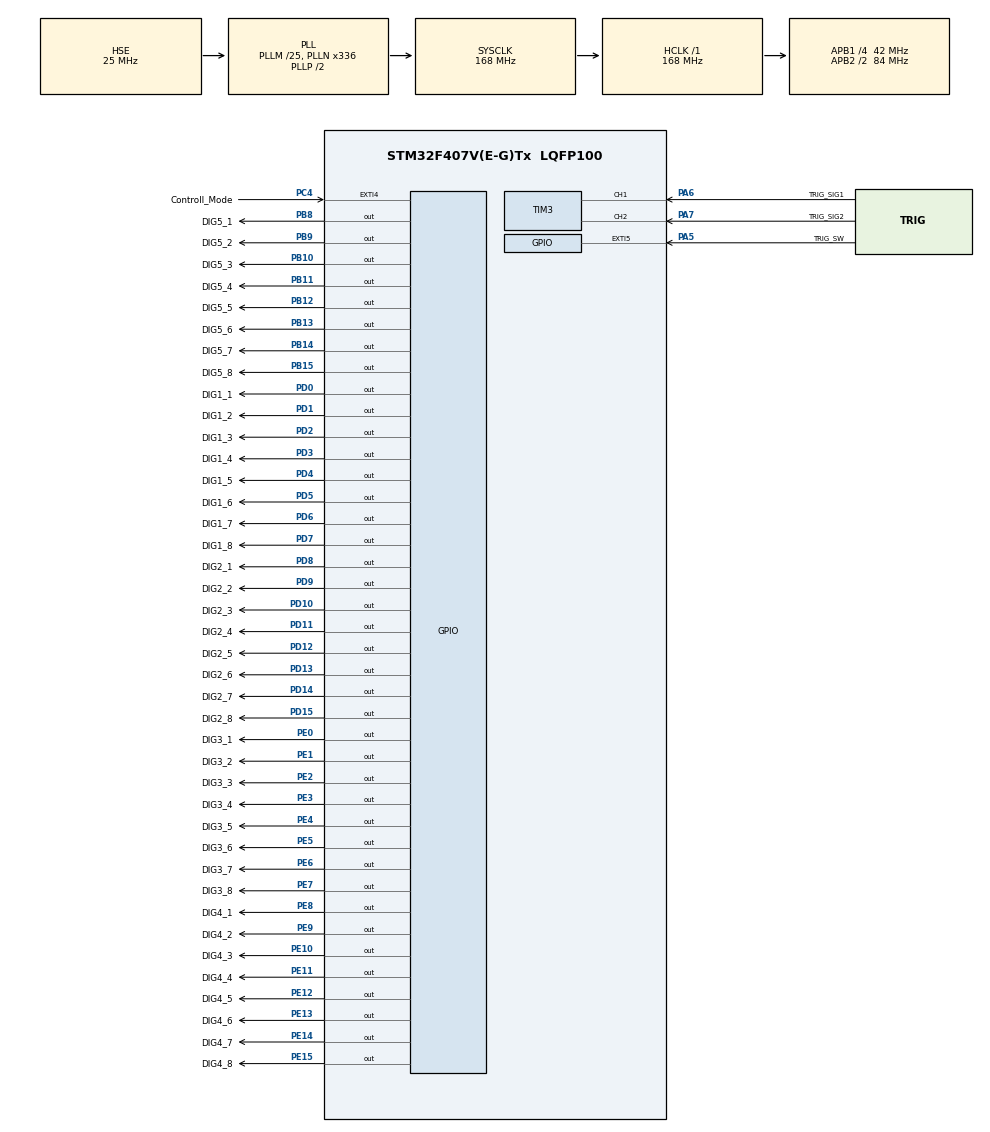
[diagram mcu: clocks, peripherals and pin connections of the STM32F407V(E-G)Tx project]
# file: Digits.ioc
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Mcu.Family=STM32F4
Mcu.Name=STM32F407V(E-G)Tx
Mcu.Package=LQFP100
NVIC.EXTI4_IRQn=true\:2\:0\:false\:false\:true\:true\:true\:true
NVIC.EXTI9_5_IRQn=true\:1\:0\:false\:false\:true\:true\:true\:true
NVIC.PriorityGroup=NVIC_PRIORITYGROUP_4
NVIC.TIM2_IRQn=true\:0\:0\:false\:false\:true\:true\:true\:true
NVIC.TIM3_IRQn=true\:0\:0\:false\:false\:true\:true\:true\:true
PA13.Mode=Serial_Wire
PA13.Signal=SYS_JTMS-SWDIO
PA14.Mode=Serial_Wire
PA14.Signal=SYS_JTCK-SWCLK
PA5.GPIO_Label=TRIG_SW
PA5.GPIO_ModeDefaultEXTI=GPIO_MODE_IT_RISING_FALLING
PA5.Signal=GPXTI5
PA6.GPIO_Label=TRIG_SIG1
PA6.Signal=S_TIM3_CH1
PA7.GPIO_Label=TRIG_SIG2
PA7.Signal=S_TIM3_CH2
PB10.GPIO_Label=DIG5_3
PB10.GPIO_Speed=GPIO_SPEED_FREQ_HIGH
PB10.PinState=GPIO_PIN_SET
PB10.Signal=GPIO_Output
PB11.GPIO_Label=DIG5_4
PB11.GPIO_Speed=GPIO_SPEED_FREQ_HIGH
PB11.PinState=GPIO_PIN_SET
PB11.Signal=GPIO_Output
PB12.GPIO_Label=DIG5_5
PB12.GPIO_Speed=GPIO_SPEED_FREQ_HIGH
PB12.PinState=GPIO_PIN_SET
PB12.Signal=GPIO_Output
PB13.GPIO_Label=DIG5_6
PB13.GPIO_Speed=GPIO_SPEED_FREQ_HIGH
PB13.PinState=GPIO_PIN_SET
PB13.Signal=GPIO_Output
PB14.GPIO_Label=DIG5_7
PB14.GPIO_Speed=GPIO_SPEED_FREQ_HIGH
PB14.PinState=GPIO_PIN_SET
PB14.Signal=GPIO_Output
PB15.GPIO_Label=DIG5_8
PB15.GPIO_Speed=GPIO_SPEED_FREQ_HIGH
PB15.PinState=GPIO_PIN_SET
PB15.Signal=GPIO_Output
PB8.GPIO_Label=DIG5_1
PB8.GPIO_Speed=GPIO_SPEED_FREQ_HIGH
PB8.PinState=GPIO_PIN_SET
PB8.Signal=GPIO_Output
PB9.GPIO_Label=DIG5_2
PB9.GPIO_Speed=GPIO_SPEED_FREQ_HIGH
PB9.PinState=GPIO_PIN_SET
PB9.Signal=GPIO_Output
PC4.GPIO_Label=Controll_Mode
PC4.GPIO_ModeDefaultEXTI=GPIO_MODE_IT_RISING_FALLING
PC4.Signal=GPXTI4
PD0.GPIO_Label=DIG1_1
PD0.GPIO_Speed=GPIO_SPEED_FREQ_HIGH
PD0.PinState=GPIO_PIN_SET
PD0.Signal=GPIO_Output
PD1.GPIO_Label=DIG1_2
PD1.GPIO_Speed=GPIO_SPEED_FREQ_HIGH
PD1.PinState=GPIO_PIN_SET
PD1.Signal=GPIO_Output
PD10.GPIO_Label=DIG2_3
PD10.GPIO_Speed=GPIO_SPEED_FREQ_HIGH
PD10.PinState=GPIO_PIN_SET
PD10.Signal=GPIO_Output
PD11.GPIO_Label=DIG2_4
PD11.GPIO_Speed=GPIO_SPEED_FREQ_HIGH
PD11.PinState=GPIO_PIN_SET
PD11.Signal=GPIO_Output
PD12.GPIO_Label=DIG2_5
PD12.GPIO_Speed=GPIO_SPEED_FREQ_HIGH
PD12.PinState=GPIO_PIN_SET
PD12.Signal=GPIO_Output
PD13.GPIO_Label=DIG2_6
PD13.GPIO_Speed=GPIO_SPEED_FREQ_HIGH
PD13.PinState=GPIO_PIN_SET
PD13.Signal=GPIO_Output
PD14.GPIO_Label=DIG2_7
PD14.GPIO_Speed=GPIO_SPEED_FREQ_HIGH
PD14.PinState=GPIO_PIN_SET
PD14.Signal=GPIO_Output
PD15.GPIO_Label=DIG2_8
PD15.GPIO_Speed=GPIO_SPEED_FREQ_HIGH
PD15.PinState=GPIO_PIN_SET
PD15.Signal=GPIO_Output
PD2.GPIO_Label=DIG1_3
PD2.GPIO_Speed=GPIO_SPEED_FREQ_HIGH
PD2.PinState=GPIO_PIN_SET
PD2.Signal=GPIO_Output
PD3.GPIO_Label=DIG1_4
PD3.GPIO_Speed=GPIO_SPEED_FREQ_HIGH
PD3.PinState=GPIO_PIN_SET
PD3.Signal=GPIO_Output
PD4.GPIO_Label=DIG1_5
PD4.GPIO_Speed=GPIO_SPEED_FREQ_HIGH
PD4.PinState=GPIO_PIN_SET
PD4.Signal=GPIO_Output
PD5.GPIO_Label=DIG1_6
PD5.GPIO_Speed=GPIO_SPEED_FREQ_HIGH
PD5.PinState=GPIO_PIN_SET
PD5.Signal=GPIO_Output
PD6.GPIO_Label=DIG1_7
PD6.GPIO_Speed=GPIO_SPEED_FREQ_HIGH
PD6.PinState=GPIO_PIN_SET
PD6.Signal=GPIO_Output
PD7.GPIO_Label=DIG1_8
PD7.GPIO_Speed=GPIO_SPEED_FREQ_HIGH
PD7.PinState=GPIO_PIN_SET
PD7.Signal=GPIO_Output
PD8.GPIO_Label=DIG2_1
PD8.GPIO_Speed=GPIO_SPEED_FREQ_HIGH
PD8.PinState=GPIO_PIN_SET
PD8.Signal=GPIO_Output
PD9.GPIO_Label=DIG2_2
PD9.GPIO_Speed=GPIO_SPEED_FREQ_HIGH
PD9.PinState=GPIO_PIN_SET
PD9.Signal=GPIO_Output
PE0.GPIO_Label=DIG3_1
PE0.GPIO_Speed=GPIO_SPEED_FREQ_HIGH
PE0.PinState=GPIO_PIN_SET
PE0.Signal=GPIO_Output
PE1.GPIO_Label=DIG3_2
PE1.GPIO_Speed=GPIO_SPEED_FREQ_HIGH
PE1.PinState=GPIO_PIN_SET
PE1.Signal=GPIO_Output
PE10.GPIO_Label=DIG4_3
PE10.GPIO_Speed=GPIO_SPEED_FREQ_HIGH
PE10.PinState=GPIO_PIN_SET
PE10.Signal=GPIO_Output
PE11.GPIO_Label=DIG4_4
PE11.GPIO_Speed=GPIO_SPEED_FREQ_HIGH
PE11.PinState=GPIO_PIN_SET
PE11.Signal=GPIO_Output
PE12.GPIO_Label=DIG4_5
PE12.GPIO_Speed=GPIO_SPEED_FREQ_HIGH
PE12.PinState=GPIO_PIN_SET
PE12.Signal=GPIO_Output
PE13.GPIO_Label=DIG4_6
PE13.GPIO_Speed=GPIO_SPEED_FREQ_HIGH
PE13.PinState=GPIO_PIN_SET
PE13.Signal=GPIO_Output
PE14.GPIO_Label=DIG4_7
PE14.GPIO_Speed=GPIO_SPEED_FREQ_HIGH
PE14.PinState=GPIO_PIN_SET
PE14.Signal=GPIO_Output
PE15.GPIO_Label=DIG4_8
PE15.GPIO_Speed=GPIO_SPEED_FREQ_HIGH
PE15.PinState=GPIO_PIN_SET
PE15.Signal=GPIO_Output
PE2.GPIO_Label=DIG3_3
PE2.GPIO_Speed=GPIO_SPEED_FREQ_HIGH
PE2.PinState=GPIO_PIN_SET
PE2.Signal=GPIO_Output
PE3.GPIO_Label=DIG3_4
PE3.GPIO_Speed=GPIO_SPEED_FREQ_HIGH
PE3.PinState=GPIO_PIN_SET
PE3.Signal=GPIO_Output
PE4.GPIO_Label=DIG3_5
PE4.GPIO_Speed=GPIO_SPEED_FREQ_HIGH
PE4.PinState=GPIO_PIN_SET
PE4.Signal=GPIO_Output
PE5.GPIO_Label=DIG3_6
PE5.GPIO_Speed=GPIO_SPEED_FREQ_HIGH
PE5.PinState=GPIO_PIN_SET
PE5.Signal=GPIO_Output
PE6.GPIO_Label=DIG3_7
PE6.GPIO_Speed=GPIO_SPEED_FREQ_HIGH
PE6.PinState=GPIO_PIN_SET
PE6.Signal=GPIO_Output
PE7.GPIO_Label=DIG3_8
PE7.GPIO_Speed=GPIO_SPEED_FREQ_HIGH
PE7.PinState=GPIO_PIN_SET
PE7.Signal=GPIO_Output
PE8.GPIO_Label=DIG4_1
PE8.GPIO_Speed=GPIO_SPEED_FREQ_HIGH
PE8.PinState=GPIO_PIN_SET
PE8.Signal=GPIO_Output
PE9.GPIO_Label=DIG4_2
PE9.GPIO_Speed=GPIO_SPEED_FREQ_HIGH
PE9.PinState=GPIO_PIN_SET
PE9.Signal=GPIO_Output
PH0-OSC_IN.Mode=HSE-External-Oscillator
PH0-OSC_IN.Signal=RCC_OSC_IN
PH1-OSC_OUT.Mode=HSE-External-Oscillator
PH1-OSC_OUT.Signal=RCC_OSC_OUT
ProjectManager.HeapSize=0x200
ProjectManager.StackSize=0x400
ProjectManager.TargetToolchain=MDK-ARM V5
RCC.48MHZClocksFreq_Value=48000000
RCC.AHBFreq_Value=168000000
RCC.APB1CLKDivider=RCC_HCLK_DIV4
RCC.APB1Freq_Value=42000000
RCC.APB1TimFreq_Value=84000000
RCC.APB2CLKDivider=RCC_HCLK_DIV2
RCC.APB2Freq_Value=84000000
RCC.APB2TimFreq_Value=168000000
RCC.CortexFreq_Value=168000000
RCC.HCLKFreq_Value=168000000
RCC.HSE_VALUE=25000000
RCC.HSI_VALUE=16000000
RCC.LSE_VALUE=32768
RCC.PLLM=25
RCC.PLLN=336
RCC.PLLQ=7
RCC.PLLSourceVirtual=RCC_PLLSOURCE_HSE
RCC.SYSCLKFreq_VALUE=168000000
RCC.SYSCLKSource=RCC_SYSCLKSOURCE_PLLCLK
RCC.VCOOutputFreq_Value=336000000
SH.S_TIM3_CH1.0=TIM3_CH1,Input_Capture1_from_TI1
SH.S_TIM3_CH2.0=TIM3_CH2,Input_Capture2_from_TI2
TIM2.Period=83
TIM3.Channel-Input_Capture1_from_TI1=TIM_CHANNEL_1
TIM3.Channel-Input_Capture2_from_TI2=TIM_CHANNEL_2
VP_TIM2_VS_ClockSourceINT.Mode=Internal
board=custom

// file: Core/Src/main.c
/* USER CODE BEGIN Header */
/**
  ******************************************************************************
  * @file           : main.c
  * @brief          : Main program body
  ******************************************************************************
  * @attention
  *
  * Copyright (c) 2026 STMicroelectronics.
  * All rights reserved.
  *
  * This software is licensed under terms that can be found in the LICENSE file
  * in the root directory of this software component.
  * If no LICENSE file comes with this software, it is provided AS-IS.
  *
  ******************************************************************************
  */
/* USER CODE END Header */
#include "main.h"
#include "tim.h"
#include "gpio.h"

/* USER CODE BEGIN Includes */
#include "display.h"
/* USER CODE END Includes */

void SystemClock_Config(void);

int main(void)
{

  /* MCU Configuration--------------------------------------------------------*/

  /* Reset of all peripherals, Initializes the Flash interface and the Systick. */
  HAL_Init();

  /* Configure the system clock */
  SystemClock_Config();

  /* Initialize all configured peripherals */
  MX_GPIO_Init();
  MX_TIM2_Init();
  MX_TIM3_Init();
  /* USER CODE BEGIN 2 */
  Display_Start();
  /* USER CODE END 2 */

  /* Infinite loop */
  while (1)
  {

    /* USER CODE BEGIN 3 */
    __WFI();
  }
  /* USER CODE END 3 */
}

void SystemClock_Config(void)
{
  RCC_OscInitTypeDef RCC_OscInitStruct = {0};
  RCC_ClkInitTypeDef RCC_ClkInitStruct = {0};

  /** Configure the main internal regulator output voltage
  */
  __HAL_RCC_PWR_CLK_ENABLE();
  __HAL_PWR_VOLTAGESCALING_CONFIG(PWR_REGULATOR_VOLTAGE_SCALE1);

  /** Initializes the RCC Oscillators according to the specified parameters
  * in the RCC_OscInitTypeDef structure.
  */
  RCC_OscInitStruct.OscillatorType = RCC_OSCILLATORTYPE_HSE;
  RCC_OscInitStruct.HSEState = RCC_HSE_ON;
  RCC_OscInitStruct.PLL.PLLState = RCC_PLL_ON;
  RCC_OscInitStruct.PLL.PLLSource = RCC_PLLSOURCE_HSE;
  RCC_OscInitStruct.PLL.PLLM = 25;
  RCC_OscInitStruct.PLL.PLLN = 336;
  RCC_OscInitStruct.PLL.PLLP = RCC_PLLP_DIV2;
  RCC_OscInitStruct.PLL.PLLQ = 7;
  if (HAL_RCC_OscConfig(&RCC_OscInitStruct) != HAL_OK)
  {
    Error_Handler();
  }

  /** Initializes the CPU, AHB and APB buses clocks
  */
  RCC_ClkInitStruct.ClockType = RCC_CLOCKTYPE_HCLK|RCC_CLOCKTYPE_SYSCLK
                              |RCC_CLOCKTYPE_PCLK1|RCC_CLOCKTYPE_PCLK2;
  RCC_ClkInitStruct.SYSCLKSource = RCC_SYSCLKSOURCE_PLLCLK;
  RCC_ClkInitStruct.AHBCLKDivider = RCC_SYSCLK_DIV1;
  RCC_ClkInitStruct.APB1CLKDivider = RCC_HCLK_DIV4;
  RCC_ClkInitStruct.APB2CLKDivider = RCC_HCLK_DIV2;

  if (HAL_RCC_ClockConfig(&RCC_ClkInitStruct, FLASH_LATENCY_5) != HAL_OK)
  {
    Error_Handler();
  }
}

void Error_Handler(void)
{
  __disable_irq();
  while (1)
  {
  }
}
